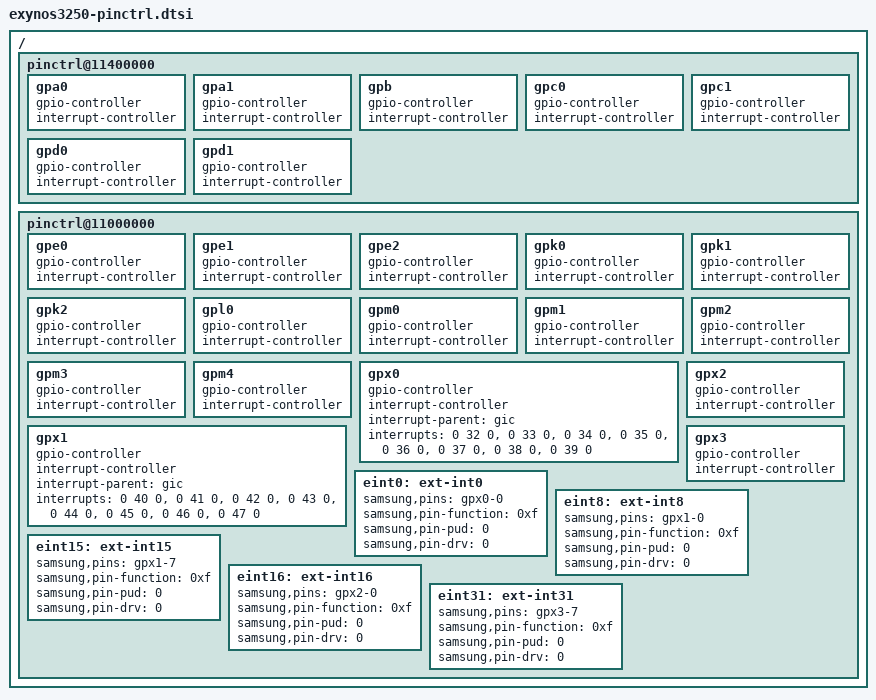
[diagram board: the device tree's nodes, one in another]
/*
 * Samsung's Exynos3250 SoCs pin-mux and pin-config device tree source
 *
 * Copyright (c) 2012 Samsung Electronics Co., Ltd.
 *		http://www.samsung.com
 *
 * Samsung's Exynos3250 SoCs pin-mux and pin-config optiosn are listed as device
 * tree nodes are listed in this file.
 *
 * This program is free software; you can redistribute it and/or modify
 * it under the terms of the GNU General Public License version 2 as
 * published by the Free Software Foundation.
*/

/ {
	pinctrl@11400000 {
		gpa0: gpa0 {
			gpio-controller;
			#gpio-cells = <2>;

			interrupt-controller;
			#interrupt-cells = <2>;
		};

		gpa1: gpa1 {
			gpio-controller;
			#gpio-cells = <2>;

			interrupt-controller;
			#interrupt-cells = <2>;
		};

		gpb: gpb {
			gpio-controller;
			#gpio-cells = <2>;

			interrupt-controller;
			#interrupt-cells = <2>;
		};

		gpc0: gpc0 {
			gpio-controller;
			#gpio-cells = <2>;

			interrupt-controller;
			#interrupt-cells = <2>;
		};

		gpc1: gpc1 {
			gpio-controller;
			#gpio-cells = <2>;

			interrupt-controller;
			#interrupt-cells = <2>;
		};

		gpd0: gpd0 {
			gpio-controller;
			#gpio-cells = <2>;

			interrupt-controller;
			#interrupt-cells = <2>;
		};

		gpd1: gpd1 {
			gpio-controller;
			#gpio-cells = <2>;

			interrupt-controller;
			#interrupt-cells = <2>;
		};
	};

	pinctrl@11000000 {
		gpe0: gpe0 {
			gpio-controller;
			#gpio-cells = <2>;

			interrupt-controller;
			#interrupt-cells = <2>;
		};

		gpe1: gpe1 {
			gpio-controller;
			#gpio-cells = <2>;

			interrupt-controller;
			#interrupt-cells = <2>;
		};

		gpe2: gpe2 {
			gpio-controller;
			#gpio-cells = <2>;

			interrupt-controller;
			#interrupt-cells = <2>;
		};

		gpk0: gpk0 {
			gpio-controller;
			#gpio-cells = <2>;

			interrupt-controller;
			#interrupt-cells = <2>;
		};

		gpk1: gpk1 {
			gpio-controller;
			#gpio-cells = <2>;

			interrupt-controller;
			#interrupt-cells = <2>;
		};

		gpk2: gpk2 {
			gpio-controller;
			#gpio-cells = <2>;

			interrupt-controller;
			#interrupt-cells = <2>;
		};

		gpl0: gpl0 {
			gpio-controller;
			#gpio-cells = <2>;

			interrupt-controller;
			#interrupt-cells = <2>;
		};

		gpm0: gpm0 {
			gpio-controller;
			#gpio-cells = <2>;

			interrupt-controller;
			#interrupt-cells = <2>;
		};

		gpm1: gpm1 {
			gpio-controller;
			#gpio-cells = <2>;

			interrupt-controller;
			#interrupt-cells = <2>;
		};

		gpm2: gpm2 {
			gpio-controller;
			#gpio-cells = <2>;

			interrupt-controller;
			#interrupt-cells = <2>;
		};

		gpm3: gpm3 {
			gpio-controller;
			#gpio-cells = <2>;

			interrupt-controller;
			#interrupt-cells = <2>;
		};

		gpm4: gpm4 {
			gpio-controller;
			#gpio-cells = <2>;

			interrupt-controller;
			#interrupt-cells = <2>;
		};

		gpx0: gpx0 {
			gpio-controller;
			#gpio-cells = <2>;

			interrupt-controller;
			#interrupt-cells = <3>;
			interrupt-parent = <&gic>;
			interrupts = <0 32 0>, <0 33 0>, <0 34 0>, <0 35 0>,
				     <0 36 0>, <0 37 0>, <0 38 0>, <0 39 0>;
		};

		gpx1: gpx1 {
			gpio-controller;
			#gpio-cells = <2>;

			interrupt-controller;
			#interrupt-cells = <3>;
			interrupt-parent = <&gic>;
			interrupts = <0 40 0>, <0 41 0>, <0 42 0>, <0 43 0>,
				     <0 44 0>, <0 45 0>, <0 46 0>, <0 47 0>;
		};

		gpx2: gpx2 {
			gpio-controller;
			#gpio-cells = <2>;

			interrupt-controller;
			#interrupt-cells = <2>;
		};

		gpx3: gpx3 {
			gpio-controller;
			#gpio-cells = <2>;

			interrupt-controller;
			#interrupt-cells = <2>;
		};


		eint0: ext-int0 {
			samsung,pins = "gpx0-0";
			samsung,pin-function = <0xf>;
			samsung,pin-pud = <0>;
			samsung,pin-drv = <0>;
		};

		eint8: ext-int8 {
			samsung,pins = "gpx1-0";
			samsung,pin-function = <0xf>;
			samsung,pin-pud = <0>;
			samsung,pin-drv = <0>;
		};

		eint15: ext-int15 {
			samsung,pins = "gpx1-7";
			samsung,pin-function = <0xf>;
			samsung,pin-pud = <0>;
			samsung,pin-drv = <0>;
		};

		eint16: ext-int16 {
			samsung,pins = "gpx2-0";
			samsung,pin-function = <0xf>;
			samsung,pin-pud = <0>;
			samsung,pin-drv = <0>;
		};

		eint31: ext-int31 {
			samsung,pins = "gpx3-7";
			samsung,pin-function = <0xf>;
			samsung,pin-pud = <0>;
			samsung,pin-drv = <0>;
		};
	};

};
